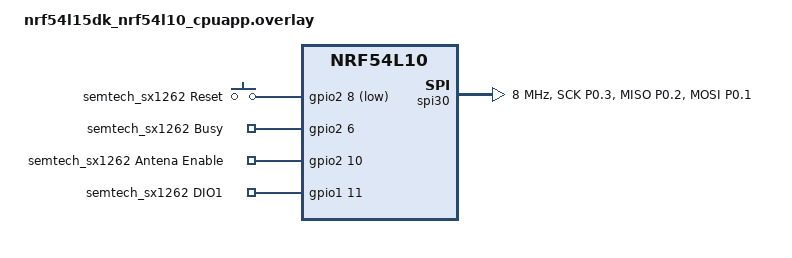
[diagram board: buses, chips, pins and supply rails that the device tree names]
/*
 * Copyright (c) 2024 Nordic Semiconductor ASA
 *
 * SPDX-License-Identifier: LicenseRef-Nordic-5-Clause
 */

 /{
	semtech_sx1262_gpios{
		compatible = "gpio-keys";
		semtech_sx1262_reset_gpios: reset {
			gpios = <&gpio2 8  (GPIO_ACTIVE_LOW|GPIO_PULL_UP)>;
			label = "semtech_sx1262 Reset";
		};
		semtech_sx1262_busy_gpios: busy {
			gpios = <&gpio2 6 (GPIO_ACTIVE_HIGH)>;
			label = "semtech_sx1262 Busy";
		};
		semtech_sx1262_antenna_enable_gpios: antena_enable {
			gpios = <&gpio2 10 (GPIO_ACTIVE_HIGH)>;
			label = "semtech_sx1262 Antena Enable";
		};
		semtech_sx1262_dio1_gpios: dio1 {
			gpios = <&gpio1 11  (GPIO_ACTIVE_HIGH|GPIO_PULL_DOWN)>;
			label = "semtech_sx1262 DIO1";
		};
	};
};

sid_semtech: &spi30 {
	compatible = "nordic,nrf-spim";
	status = "okay";
	cs-gpios = <&gpio0 0 GPIO_ACTIVE_LOW>;
	pinctrl-0 = <&spi30_default_alt>;
	pinctrl-1 = <&spi30_sleep_alt>;
	pinctrl-names = "default", "sleep";
	clock-frequency = <DT_FREQ_M(8)>;
};

&cpuapp_rram {
	reg = <0x0 DT_SIZE_K(1524)>;
};

&cpuapp_sram {
	reg = <0x20000000 DT_SIZE_K(256)>;
	ranges = <0x0 0x20000000  0x40000>;
};

&pinctrl {
	spi30_default_alt: spi30_default_alt {
		group1 {
			psels = <NRF_PSEL(SPIM_SCK, 0, 3)>,
				<NRF_PSEL(SPIM_MISO, 0, 2)>,
				<NRF_PSEL(SPIM_MOSI, 0, 1)>;
		};
	};

	spi30_sleep_alt: spi30_sleep_alt {
		group1 {
			psels = <NRF_PSEL(SPIM_SCK, 0, 3)>,
				<NRF_PSEL(SPIM_MISO, 0, 2)>,
				<NRF_PSEL(SPIM_MOSI, 0, 1)>;
			low-power-enable;
		};
	};
};

// TODO: re-enable HWFC once it's fixed
&uart20 {
	/delete-property/ hw-flow-control;
};
